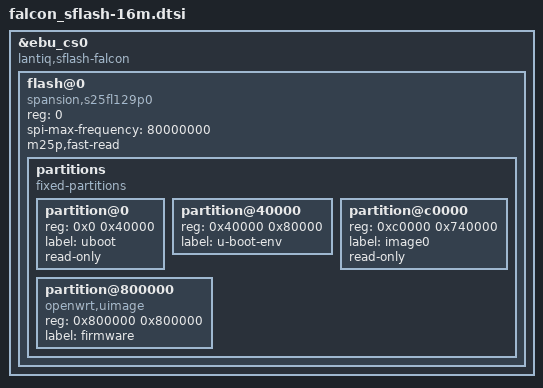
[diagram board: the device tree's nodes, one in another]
// SPDX-License-Identifier: GPL-2.0-only

&ebu_cs0 {
	/delete-property/ ranges;
	#address-cells = <1>;
	#size-cells = <0>;
	compatible = "lantiq,sflash-falcon";

	flash@0 {
		compatible = "spansion,s25fl129p0", "spansion,s25fl129p1", "jedec,spi-nor";
		reg = <0>;
		spi-max-frequency = <80000000>;
		m25p,fast-read;

		partitions {
			compatible = "fixed-partitions";
			#address-cells = <1>;
			#size-cells = <1>;

			partition@0 {
				reg = <0x0 0x40000>;
				label = "uboot";
				read-only;
			};

			partition@40000 {
				reg = <0x40000 0x80000>;
				label = "u-boot-env";
			};

			partition@c0000 {
				reg = <0xc0000 0x740000>;
				label = "image0";
				read-only;
			};

			partition@800000 {
				reg = <0x800000 0x800000>;
				label = "firmware";
				compatible = "openwrt,uimage", "denx,uimage";
			};
		};
	};
};
